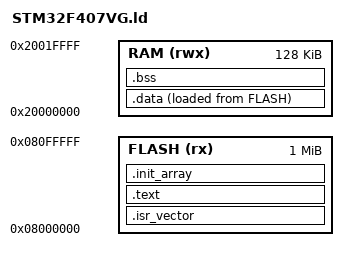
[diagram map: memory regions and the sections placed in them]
/* STM32F407VG.ld — linker script for STM32F407VG (1 MB flash, 192 KB RAM).
 *
 * Flash : 1024 KB @ 0x08000000
 * SRAM  :  128 KB @ 0x20000000 (SRAM1+SRAM2; 64 KB CCM at 0x10000000 unused) */

ENTRY(Reset_Handler)

MEMORY
{
    FLASH (rx)  : ORIGIN = 0x08000000, LENGTH = 1024K
    RAM   (rwx) : ORIGIN = 0x20000000, LENGTH = 128K
}

/* Top of stack = end of RAM (full-descending stack). */
_estack = ORIGIN(RAM) + LENGTH(RAM);

SECTIONS
{
    /* Vector table must sit at the start of flash. */
    .isr_vector :
    {
        . = ALIGN(4);
        KEEP(*(.isr_vector))
        . = ALIGN(4);
    } > FLASH

    /* Code and read-only data. */
    .text :
    {
        . = ALIGN(4);
        *(.text)
        *(.text*)
        *(.rodata)
        *(.rodata*)
        *(.glue_7)
        *(.glue_7t)
        . = ALIGN(4);
        _etext = .;
    } > FLASH

    /* C++ static constructor table. */
    .init_array :
    {
        . = ALIGN(4);
        __init_array_start = .;
        KEEP(*(SORT(.init_array.*)))
        KEEP(*(.init_array))
        __init_array_end = .;
        . = ALIGN(4);
    } > FLASH

    /* Load address of .data, used by the startup copy loop. */
    _sidata = LOADADDR(.data);

    /* Initialised data: lives in flash, copied to RAM at reset. */
    .data :
    {
        . = ALIGN(4);
        _sdata = .;
        *(.data)
        *(.data*)
        . = ALIGN(4);
        _edata = .;
    } > RAM AT > FLASH

    /* Zero-initialised data. */
    .bss :
    {
        . = ALIGN(4);
        _sbss = .;
        *(.bss)
        *(.bss*)
        *(COMMON)
        . = ALIGN(4);
        _ebss = .;
    } > RAM

    /* Discard exception-handling tables we don't use. */
    /DISCARD/ :
    {
        *(.ARM.exidx*)
        *(.ARM.extab*)
    }
}
